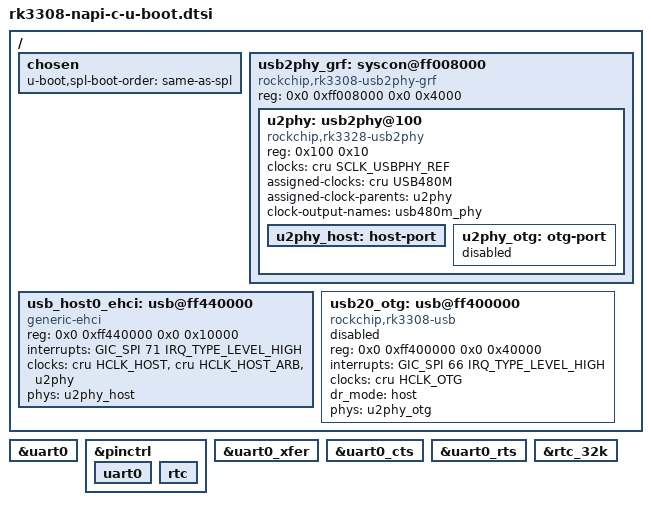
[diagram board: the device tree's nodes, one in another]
// SPDX-License-Identifier: GPL-2.0+
/*
 * (C) Copyright 2018-2019 Rockchip Electronics Co., Ltd
 */
#include "rk3308-u-boot.dtsi"
/ {
	chosen {
		u-boot,spl-boot-order = "same-as-spl", &emmc, &sdmmc;
	};
};
&uart0 {
	bootph-all;
};
&pinctrl {
	bootph-some-ram;
	uart0 {
		bootph-some-ram;
	};
	rtc {
		bootph-some-ram;
	};
};
&uart0_xfer {
	bootph-some-ram;
};
&uart0_cts {
	bootph-some-ram;
};
&uart0_rts {
	bootph-some-ram;
};
&rtc_32k {
	bootph-some-ram;
};

/* USB host support - usb2phy_grf + u2phy structure from mainline 2024.10,
 * compatible from vendor 2017.09 (rk3328-usb2phy, supported in 2023.10 driver).
 * rk3308.dtsi in 2023.10 lacks these nodes entirely. */
/ {
	usb2phy_grf: syscon@ff008000 {
		compatible = "rockchip,rk3308-usb2phy-grf", "syscon",
			     "simple-mfd";
		reg = <0x0 0xff008000 0x0 0x4000>;
		#address-cells = <1>;
		#size-cells = <1>;

		u2phy: usb2phy@100 {
			compatible = "rockchip,rk3328-usb2phy";
			reg = <0x100 0x10>;
			clocks = <&cru SCLK_USBPHY_REF>;
			clock-names = "phyclk";
			#clock-cells = <0>;
			assigned-clocks = <&cru USB480M>;
			assigned-clock-parents = <&u2phy>;
			clock-output-names = "usb480m_phy";
			status = "okay";

			u2phy_host: host-port {
				#phy-cells = <0>;
				status = "okay";
			};

			u2phy_otg: otg-port {
				#phy-cells = <0>;
				status = "disabled";
			};
		};
	};

	usb_host0_ehci: usb@ff440000 {
		compatible = "generic-ehci";
		reg = <0x0 0xff440000 0x0 0x10000>;
		interrupts = <GIC_SPI 71 IRQ_TYPE_LEVEL_HIGH>;
		clocks = <&cru HCLK_HOST>, <&cru HCLK_HOST_ARB>,
			 <&u2phy>;
		clock-names = "usbhost", "arbiter", "utmi";
		phys = <&u2phy_host>;
		phy-names = "usb";
		status = "okay";
	};

	usb20_otg: usb@ff400000 {
		compatible = "rockchip,rk3308-usb", "rockchip,rk3066-usb",
			     "snps,dwc2";
		reg = <0x0 0xff400000 0x0 0x40000>;
		interrupts = <GIC_SPI 66 IRQ_TYPE_LEVEL_HIGH>;
		clocks = <&cru HCLK_OTG>;
		clock-names = "otg";
		dr_mode = "host";
		phys = <&u2phy_otg>;
		phy-names = "usb2-phy";
		status = "disabled";
	};
};
